# CM0+ register map
CPU: CM0+ r0p0, selectable endian, MPU, no FPU, 2 interrupt priority bits
Registers are 32-bit, read-write, reset 0x0 unless marked. A register's access mark holds for its fields unless they carry their own. Offsets are from the block's base; [hi:lo] are bit positions; lines under a group give offsets from that group; {n}, {i} and the like mark numbered series.

## NVIC — Nested Vectored Interrupt Controller
Base 0xE000E100
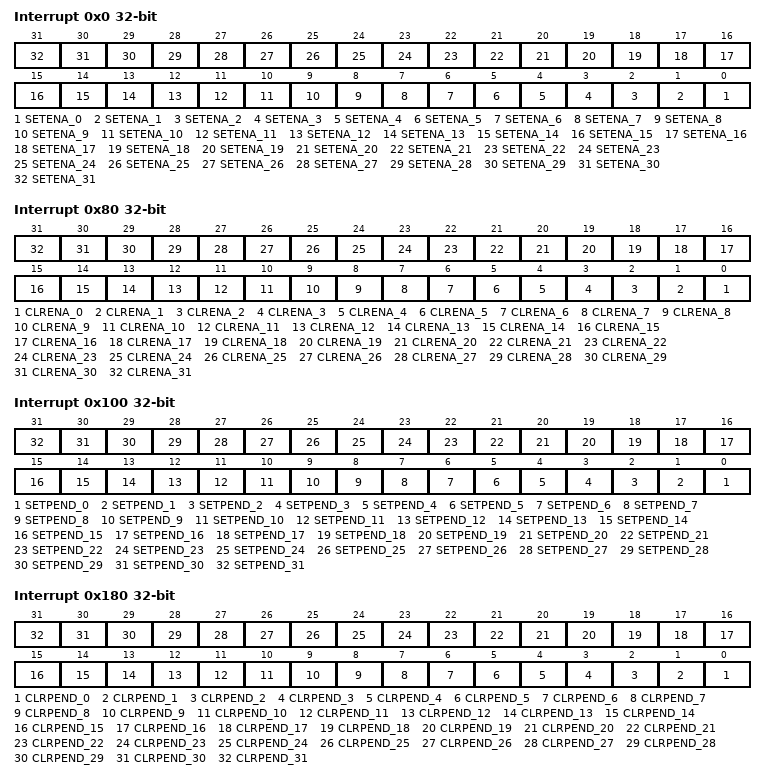
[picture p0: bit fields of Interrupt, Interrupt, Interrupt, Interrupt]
{0x0+4i} Interrupt Set-Enable Register {i} (i=0..0) — Enables, or reads the enable state of a group of interrupts
  [n] SETENA_{n} (n=0..31) write-1-sets — For register NVIC_ISERn, enables or shows the current enabled state of interrupt (m+(32*n))
    0=No effect; 1=Enable interrupt
{0x80+4i} Interrupt Clear-Enable Register {i} (i=0..0) — Disables, or reads the enable state of, a group of registers
  [n] CLRENA_{n} (n=0..31) write-1-clears — For register NVIC_ICERn, disables or shows the current enabled state of interrupt (m+(32*n))
    0=No effect; 1=Disable interrupt
{0x100+4i} Interrupt Set-Pending Register {i} (i=0..0) — For a group of interrupts, changes interrupt status to pending, or shows the current pending status
  [n] SETPEND_{n} (n=0..31) write-1-sets — For register NVIC_ISPRn, changes the state of interrupt (m+(32*n)) to pending, or shows whether the state of the interrupt is pending
    0=No effect; 1=Pend interrupt
{0x180+4i} Interrupt Clear-Pending Register {i} (i=0..0) — For a group of interrupts, clears the interrupt pending status, or shows the current pending status
  [n] CLRPEND_{n} (n=0..31) write-1-clears — For register NVIC_ICPRn, clears the pending state of interrupt (m+(32*n)), or shows whether the state of the interrupt is pending
    0=No effect; 1=Clear pending state of interrupt
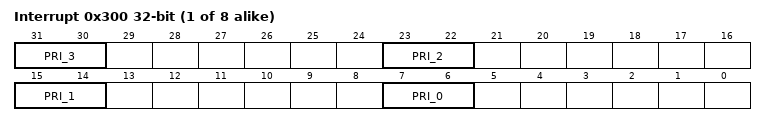
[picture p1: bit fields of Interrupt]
{0x300+4i} Interrupt Priority Register {i} (i=0..7) — Sets or reads interrupt priorities
  [8n+7:8n+6] PRI_{n} (n=0..3) — Priority of interrupt 4n+m. The Cortex-M0+ implements the top two bits of each byte, [7:6]; the rest read as zero and ignore writes

## MPU — Memory Protection Unit
Base 0xE000ED90
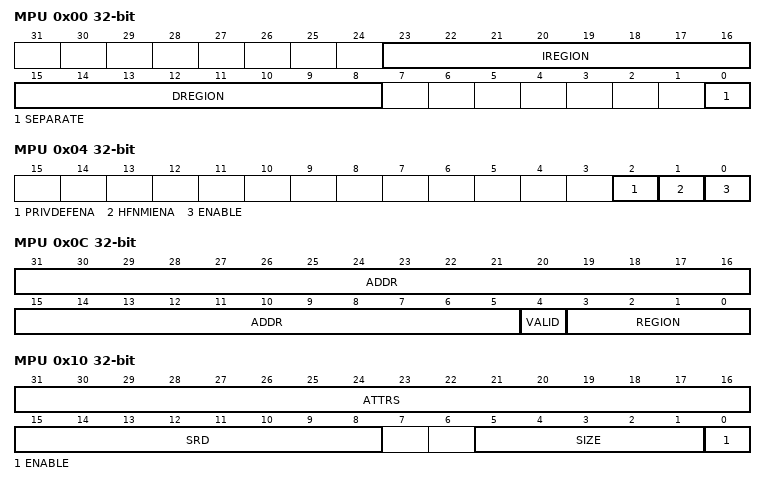
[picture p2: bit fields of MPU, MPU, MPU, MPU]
0x00 MPU Type Register ro — The MPU Type Register indicates how many regions the MPU support
  [23:16] IREGION — Instruction region
  [15:8] DREGION — Number of regions supported by the MPU
  [0] SEPARATE — Indicates support for separate instruction and data address maps. RAZ. ARMv6-M only supports a unified MPU
0x04 MPU Control Register — Enables the MPU, and when the MPU is enabled, controls whether the default memory map is enabled as a background region for privileged accesses, and whether the MPU is enabled for HardFaults, NMIs
  [2] PRIVDEFENA — When the ENABLE bit is set to 1, the meaning of this bit is
    0=Disables the default memory map; 1=Enables the default memory map as a background region for privileged access
  [1] HFNMIENA — When the ENABLE bit is set to 1, controls whether handlers executing with priority less than 0 access memory with the MPU enabled or with the MPU disabled
    0=Disables the MPU for these handlers; 1=Use the MPU for memory accesses by these handlers
  [0] ENABLE — Enables the MPU
    0=The MPU is disabled; 1=The MPU is enabled
0x08 MPU Region Number Register — Selects the region currently accessed by MPU_RBAR and MPU_RASR
  [7:0] REGION — Indicates the memory region accessed by MPU_RBAR and MPU_RASR
0x0C MPU Region Base Address Register — Holds the base address of the region identified by MPU_RNR
  [31:5] ADDR — Base address of the region
  [4] VALID — On writes, indicates whether the region to update is specified by MPU_RNR
    0=Apply the base address update to the region specified by MPU_RNR.REGION; 1=Update MPU_RNR.REGION to the value obtained by zero extending the REGION value specified in this write
  [3:0] REGION — On writes, can specify the number of the region to update
0x10 MPU Region Attribute and Size Register — Defines the size and access behavior of the region identified by MPU_RNR, and enables that region
  [31:16] ATTRS — The MPU Region Attribute field
  [15:8] SRD — Subregion Disable
    0=Subregion enabled; 1=Subregion disabled
  [5:1] SIZE — Indicates the region size
  [0] ENABLE — Enables this region
    0=When the MPU is enabled, this region is disabled; 1=When the MPU is enabled, this region is enabled
